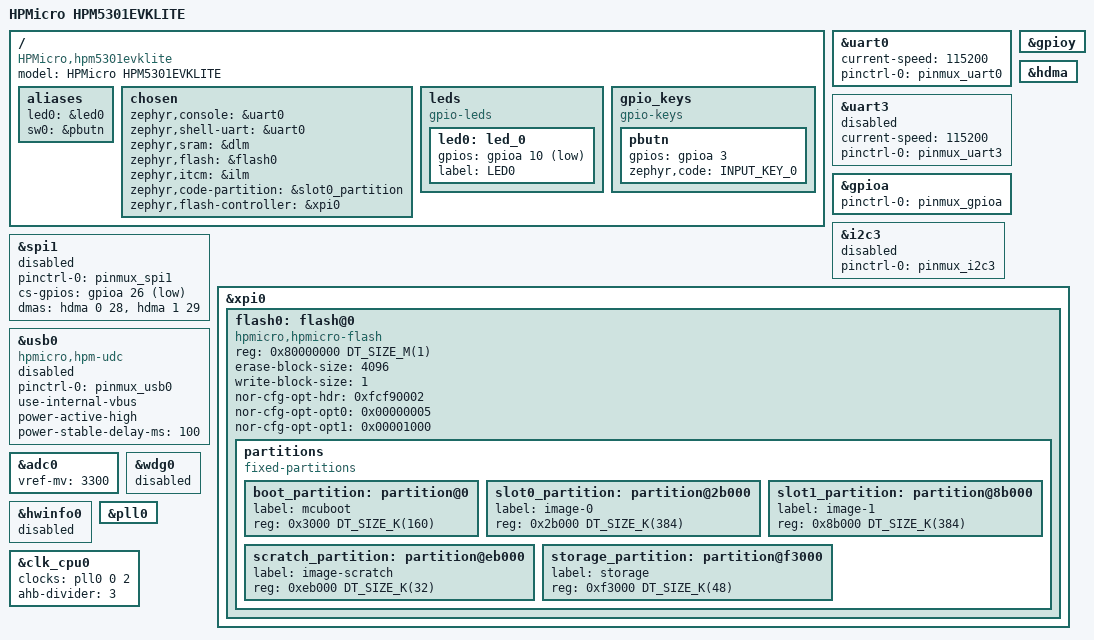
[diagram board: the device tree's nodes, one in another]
/dts-v1/;

/*
* Copyright (c) 2026 HPMicro
* SPDX-License-Identifier: Apache-2.0
*/

#include <hpmicro/HPM5300/hpm5301.dtsi>
#include "hpm5301evklite-pinctrl.dtsi"
#include <zephyr/dt-bindings/input/input-event-codes.h>

/ {
	model = "HPMicro HPM5301EVKLITE";
	compatible = "HPMicro,hpm5301evklite";
	aliases {
		led0 = &led0;
		sw0 = &pbutn;
	};

	chosen {
		zephyr,console = &uart0;
		zephyr,shell-uart = &uart0;
		zephyr,sram = &dlm;
		zephyr,flash = &flash0;
		zephyr,itcm = &ilm;
		zephyr,code-partition = &slot0_partition;
		zephyr,flash-controller = &xpi0;
	};

	leds {
		compatible = "gpio-leds";
		led0: led_0 {
			gpios = <&gpioa 10 (GPIO_PULL_UP | GPIO_ACTIVE_LOW)>;
			label = "LED0";
		};
	};

	gpio_keys {
		compatible = "gpio-keys";
		pbutn: pbutn {
			gpios = <&gpioa 3 (GPIO_PULL_DOWN | GPIO_ACTIVE_HIGH)>;
			zephyr,code = <INPUT_KEY_0>;
		};
	};
};

&uart0 {
	status = "okay";
	current-speed = <115200>;
	pinctrl-0 = <&pinmux_uart0>;
	pinctrl-names = "default";
};

&uart3 {
	status = "disabled";
	current-speed = <115200>;
	pinctrl-0 = <&pinmux_uart3>;
	pinctrl-names = "default";
};

&gpioa {
	pinctrl-0 = <&pinmux_gpioa>;
	pinctrl-names = "default";
	status = "okay";
};

&gpioy {
	status = "okay";
};

&i2c3 {
	status = "disabled";
	pinctrl-0 = <&pinmux_i2c3>;
	pinctrl-names = "default";
};

&spi1 {
	status = "disabled";
	pinctrl-0 = <&pinmux_spi1>;
	pinctrl-names = "default";
	cs-gpios = <&gpioa 26 GPIO_ACTIVE_LOW>;
	dmas = <&hdma 0 28>, <&hdma 1 29>;
	dma-names = "rx", "tx";
};

&hdma {
	status = "okay";
};

&xpi0 {
	status = "okay";
	flash0: flash@0 {
		compatible = "hpmicro,hpmicro-flash", "soc-nv-flash";
		reg = <0x80000000 DT_SIZE_M(1)>;
		status = "okay";
		erase-block-size = <4096>;
		write-block-size = <1>;
		nor-cfg-opt-hdr = <0xfcf90002>;
		nor-cfg-opt-opt0 = <0x00000005>;
		nor-cfg-opt-opt1 = <0x00001000>;
		partitions {
			compatible = "fixed-partitions";
			#address-cells = <1>;
			#size-cells = <1>;
			boot_partition: partition@0 {
				label = "mcuboot";
				reg = <0x3000 DT_SIZE_K(160)>;
			};

			slot0_partition: partition@2b000 {
				label = "image-0";
				reg = <0x2b000 DT_SIZE_K(384)>;
			};

			slot1_partition: partition@8b000 {
				label = "image-1";
				reg = <0x8b000 DT_SIZE_K(384)>;
			};

			scratch_partition: partition@eb000 {
				label = "image-scratch";
				reg = <0xeb000 DT_SIZE_K(32)>;
			};

			storage_partition: partition@f3000 {
				label = "storage";
				reg = <0xf3000 DT_SIZE_K(48)>;
			};
		};
	};
};

&usb0 {
	pinctrl-0 = <&pinmux_usb0>;
	pinctrl-names = "default";
};

zephyr_udc0: &usb0 {
	compatible = "hpmicro,hpm-udc";
	status = "disabled";
	use-internal-vbus;
	power-active-high;
	power-stable-delay-ms = <100>;
};

&adc0 {
	vref-mv = <3300>;
};

&wdg0 {
	status = "disabled";
};

&hwinfo0 {
	status = "disabled";
};

&pll0 {
	status = "okay";
};

&clk_cpu0 {
	clocks = <&pll0 0 2>;
	ahb-divider = <3>;
	status = "okay";
};
